# M0519AE_v1 register map
File version: 1.0
Registers are 32-bit, read-write, reset 0x0 unless marked. A register's access mark holds for its fields unless they carry their own. Offsets are from the block's base; [hi:lo] are bit positions; 'fields as' and 'values as' point back to an identical list.

## BPWM0 — BPWM0 Register Map
Base 0x40040000
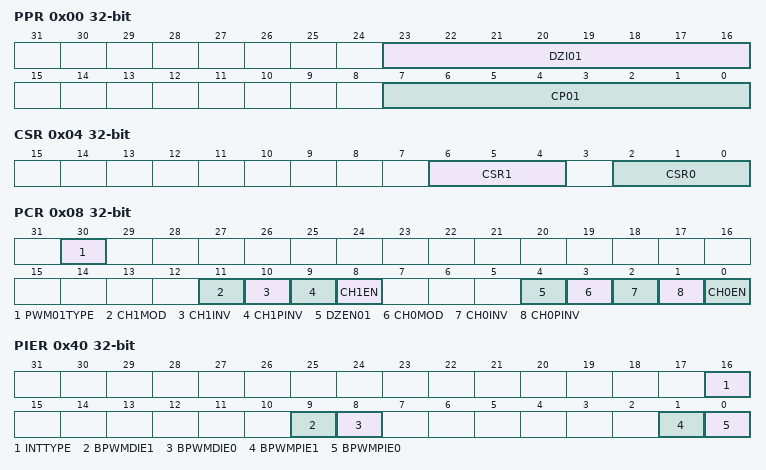
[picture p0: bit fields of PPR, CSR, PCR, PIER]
0x00 PPR — BPWM0 Prescaler Register
  [23:16] DZI01 — Dead-zone Interval for Pair of Channel 0 and Channel 1. These 8-bit determine the Dead-zone length.
  [7:0] CP01 — Clock Prescaler. Clock input is divided by (CP01 + 1) before it is fed to the corresponding BPWM-timer
0x04 CSR — BPWM0 Clock Source Divider Select Register
  [6:4] CSR1 — BPWM Timer 1 Clock Source Divider Selection. Select clock source divider for BPWM timer 1.
    0=Input clock divided by 2; 1=Input clock divided by 4; 2=Input clock divided by 8; 3=Input clock divided by 16; 4=Input clock divided by 1
  [2:0] CSR0 — BPWM Timer 0 Clock Source Divider Selection. Select clock source divider for BPWM timer 0, please refer to CSR1
0x08 PCR — BPWM0 Control Register
  [30] PWM01TYPE — BPWM0_CH0/1 Aligned Type Selection Bit
    0=Edge-aligned type; 1=Center-aligned type
  [11] CH1MOD — BPWM-timer 1 Auto-reload/One-shot Mode. Note: If there is a transition at this bit, it will cause CNR1 and CMR1 be cleared.
    0=One-shot mode; 1=Auto-reload mode
  [10] CH1INV — BPWM-timer 1 Output Inverter Enable Bit
    0=Inverter Disabled; 1=Inverter Enabled
  [9] CH1PINV — BPWM-timer 1 Output Polar Inverse Enable Bit
    0=BPWM0_CH1 output polar inverse Disabled; 1=BPWM0_CH1 output polar inverse Enabled
  [8] CH1EN — BPWM-timer 1 Enable Bit
    0=Corresponding BPWM-Timer Stopped; 1=Corresponding BPWM-Timer Start Running
  [4] DZEN01 — Dead-zone 0 Generator Enable Bit. Note: When Dead-zone generator is enabled, the pair of BPWM0_CH0 and BPWM0_CH1 becomes a complementary pair.
    0=Dead-zone 0 generator Disabled; 1=Dead-zone 0 generator Enabled
  [3] CH0MOD — BPWM-timer 0 Auto-reload/One-shot Mode. Note: If there is a transition at this bit, it will cause CNR0 and CMR0 be cleared.
    0=One-shot mode; 1=Auto-reload mode
  [2] CH0INV — BPWM-timer 0 Output Inverter Enable Bit
    0=Inverter Disabled; 1=Inverter Enabled
  [1] CH0PINV — BPWM-timer 0 Output Polar Inverse Enable Bit
    0=BPWM0_CH0 output polar inverse Disabled; 1=BPWM0_CH0 output polar inverse Enabled
  [0] CH0EN — BPWM-timer 0 Enable Bit
    0=The corresponding BPWM-Timer stops running; 1=The corresponding BPWM-Timer starts running
0x0C CNR0 — BPWM0 Counter Register 0
  [15:0] CNR — BPWM Timer Loaded Value. CNR determines the BPWM period. Note: Any write to CNR will take effect in next BPWM cycle. Note: When BPWM operating at Center-aligned type, CNR value should be set between 0x0000 to 0xFFFE. If CNR equal to 0xFFFF, the BPWM will work unpredictable. Note: When CNR value is set to 0, BPWM output is always high.
0x10 CMR0 — BPWM0 Comparator Register 0
  [15:0] CMR — BPWM Comparator Register. CMR determines the BPWM duty. Note: Any write to CMR will take effect in next BPWM cycle.
0x14 PDR0 ro — BPWM0 Data Register 0
  [15:0] PDR — BPWM Data Register. User can monitor PDR to know the current value in 16-bit counter.
0x18 CNR1 — BPWM0 Counter Register 1
  fields as CNR0
0x1C CMR1 — BPWM0 Comparator Register 1
  fields as CMR0
0x20 PDR1 ro — BPWM0 Data Register 1
  fields as PDR0
0x40 PIER — BPWM0 Interrupt Enable Register
  [16] INTTYPE — BPWM Interrupt Period Type Selection Bit. Note: This bit is effective when BPWM in Center-aligned type only.
    0=BPWMIFn will be set if BPWM counter underflow; 1=BPWMIFn will be set if BPWM counter matches CNRn register
  [9] BPWMDIE1 — BPWM Channel 1 Duty Interrupt Enable Bit
    0=BPWM0_CH1 duty interrupt Disabled; 1=BPWM0_CH1 duty interrupt Enabled
  [8] BPWMDIE0 — BPWM Channel 0 Duty Interrupt Enable Bit
    0=BPWM0_CH0 duty interrupt Disabled; 1=BPWM0_CH0 duty interrupt Enabled
  [1] BPWMPIE1 — BPWM Channel 1 Period Interrupt Enable Bit
    0=BPWM0_CH1 period interrupt Disabled; 1=BPWM0_CH1 period interrupt Enabled
  [0] BPWMPIE0 — BPWM Channel 0 Period Interrupt Enable Bit
    0=BPWM0_CH0 period interrupt Disabled; 1=BPWM0_CH0 period interrupt Enabled
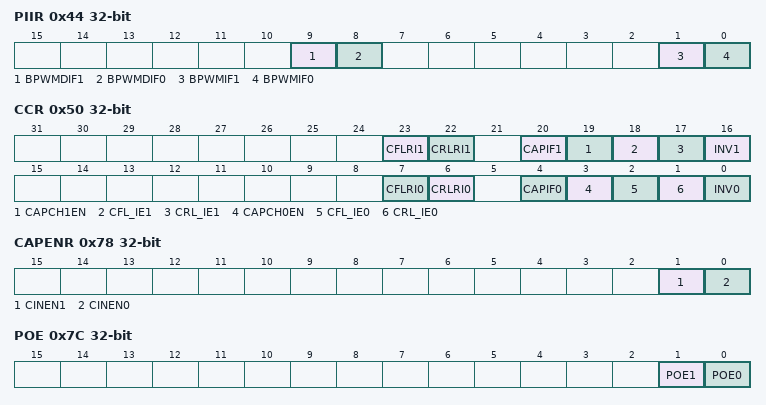
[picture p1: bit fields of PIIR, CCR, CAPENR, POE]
0x44 PIIR — BPWM0 Interrupt Indication Register
  [9] BPWMDIF1 — BPWM Channel 1 Duty Interrupt Flag. Flag is set by hardware when BPWM0_CH1 counter down count and reaches CMR1, software can clear this bit by writing a one to it. Note: If CMR equal to CNR, this flag is not working in Edge-aligned type selection
  [8] BPWMDIF0 — BPWM Channel 0 Duty Interrupt Flag. Flag is set by hardware when BPWM0_CH0 counter down count and reaches CMR0, software can clear this bit by writing a one to it. Note: If CMR equal to CNR, this flag is not working in Edge-aligned type selection
  [1] BPWMIF1 — BPWM Channel 1 Period Interrupt Flag. This bit is set by hardware when BPWM0_CH1 counter reaches the requirement of interrupt (depend on INTTYPE bit of PIER register). Note: This bit can be cleared by writing '1' to it.
  [0] BPWMIF0 — BPWM Channel 0 Period Interrupt Flag. This bit is set by hardware when BPWM0_CH0 counter reaches the requirement of interrupt (depend on INTTYPE bit of PIER register). Note: This bit can be cleared by writing '1' to it.
0x50 CCR — BPWM0 Capture Control Register
  [23] CFLRI1 — CFLR1 Latched Indicator Bit. When BPWM0 input channel 1 has a falling transition, CFLR1 was latched with the value of BPWM0 down-counter and this bit is set by hardware. Note: This bit can be cleared by writing '1' to it.
  [22] CRLRI1 — CRLR1 Latched Indicator Bit. When BPWM0 input channel 1 has a rising transition, CRLR1 was latched with the value of BPWM0 down-counter and this bit is set by hardware. Note: This bit can be cleared by writing '1' to it.
  [20] CAPIF1 — Channel 1 Capture Interrupt Indication Flag. Note: This bit can be cleared by writing '1' to it.
  [19] CAPCH1EN — Channel 1 Capture Function Enable Bit. When Enabled, Capture latched the BPWM0-counter and saved to CRLR (Rising latch) and CFLR (Falling latch). When disabled, capture does not update CRLR and CFLR, and disable BPWM0_CH1 interrupt.
    0=Capture function on BPWM0_CH1 Disabled; 1=Capture function on BPWM0_CH1 Enabled
  [18] CFL_IE1 — Channel 1 Falling Latch Interrupt Enable Bit. When enabled, if capture detects BPWM0_CH1 has falling transition, capture will issue an interrupt.
    0=Falling latch interrupt Disabled; 1=Falling latch interrupt Enabled
  [17] CRL_IE1 — Channel 1 Rising Latch Interrupt Enable Bit. When enabled, if capture detects BPWM0_CH1 has rising transition, capture will issue an interrupt.
    0=Rising latch interrupt Disabled; 1=Rising latch interrupt Enabled
  [16] INV1 — Channel 1 Inverter Enable Bit
    0=Inverter Disabled; 1=Inverter Enabled. Reverse the input signal from GPIO before fed to capture timer
  [7] CFLRI0 — CFLR0 Latched Indicator Bit. When BPWM0 input channel 0 has a falling transition, CFLR0 was latched with the value of BPWM0 down-counter and this bit is set by hardware. Note: This bit can be cleared by writing '1' to it.
  [6] CRLRI0 — CRLR0 Latched Indicator Bit. When BPWM0 input channel 0 has a rising transition, CRLR0 was latched with the value of BPWM0 down-counter and this bit is set by hardware. Note: This bit can be cleared by writing '1' to it.
  [4] CAPIF0 — Channel 0 Capture Interrupt Indication Flag. Note: This bit can be cleared by writing '1' to it.
  [3] CAPCH0EN — Channel 0 Capture Function Enable Bit. When enabled, capture latched the BPWM0-counter value and saved to CRLR (Rising latch) and CFLR (Falling latch). When disabled, capture does not update CRLR and CFLR, and disable BPWM0 channel 0 Interrupt.
    0=Capture function on BPWM0_CH0 Disabled; 1=Capture function on BPWM0_CH0 Enabled
  [2] CFL_IE0 — Channel 0 Falling Latch Interrupt Enable Bit. When Enabled, if Capture detects BPWM0 channel 0 has falling transition, Capture will issue an Interrupt.
    values as CFL_IE1
  [1] CRL_IE0 — Channel 0 Rising Latch Interrupt Enable Bit. When Enabled, if capture detects BPWM0 channel 0 has rising transition, capture will issue an interrupt.
    values as CRL_IE1
  [0] INV0 — Channel 0 Inverter Enable Bit
    values as INV1
0x58 CRLR0 ro — BPWM0 Capture Rising Latch Register (Channel 0)
  [15:0] CRLR — Capture Rising Latch Register. Latch the BPWM0 counter when Channel 0/1 has rising transition.
0x5C CFLR0 ro — BPWM0 Capture Falling Latch Register (Channel 0)
  [15:0] CFLR — Capture Falling Latch Register. Latch the BPWM0 counter when Channel 0/1 has Falling transition.
0x60 CRLR1 ro — BPWM0 Capture Rising Latch Register (Channel 1)
  fields as CRLR0
0x64 CFLR1 ro — BPWM0 Capture Falling Latch Register (Channel 1)
  fields as CFLR0
0x78 CAPENR — BPWM0 Capture Input Enable Register
  [1] CINEN1 — Channel 1 Capture Input Enable Bit
    0=BPWM0_CH1 capture input path Disabled. The input of BPWM0_CH1 capture function is always regarded as 0; 1=BPWM0_CH1 capture input path Enabled. The input of BPWM0_CH1 capture function comes from correlative multifunction pin if GPIO multi-function is set as BPWM0_CH1
  [0] CINEN0 — Channel 0 Capture Input Enable Bit
    0=BPWM0_CH0 capture input path Disabled. The input of BPWM0_CH0 capture function is always regarded as 0; 1=BPWM0_CH0 capture input path Enabled. The input of BPWM0_CH0 capture function comes from correlative multifunction pin if GPIO multi-function is set as BPWM0_CH0
0x7C POE — BPWM0 Output Enable
  [1] POE1 — Channel 1 Output Enable Bit. Note: The corresponding GPIO pin must also be switched to BPWM0 function
    0=BPWM0_CH1 output to pin Disabled; 1=BPWM0_CH1 output to pin Enabled
  [0] POE0 — Channel 0 Output Enable Bit. Note: The corresponding GPIO pin must also be switched to BPWM0 function
    0=BPWM0_CH0 output to pin Disabled; 1=BPWM0_CH0 output to pin Enabled
